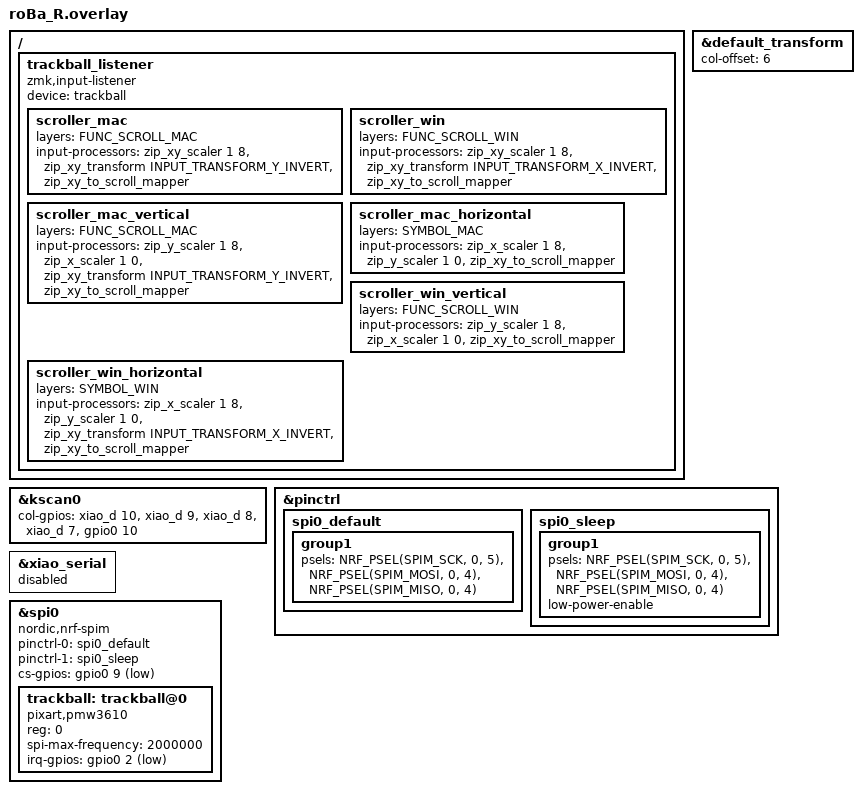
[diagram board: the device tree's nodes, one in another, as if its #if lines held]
#include "roBa.dtsi"
#include <input/processors.dtsi>
#include <dt-bindings/zmk/input_transform.h>

#define FUNC_SCROLL_WIN 6
#define FUNC_SCROLL_MAC 7


&default_transform {
    col-offset = <6>;
};

&kscan0 {
        col-gpios
            = <&xiao_d 10 GPIO_ACTIVE_HIGH>
            , <&xiao_d 9 GPIO_ACTIVE_HIGH> 
            , <&xiao_d 8 GPIO_ACTIVE_HIGH> 
            , <&xiao_d 7 GPIO_ACTIVE_HIGH> 
            , <&gpio0 10 GPIO_ACTIVE_HIGH>
            ;
};

/ {
    trackball_listener {
        compatible = "zmk,input-listener";
        device = <&trackball>;

        #ifndef MOD_SCROLL_MODE
        // Macの場合
        scroller_mac {
            layers = <FUNC_SCROLL_MAC>;
            input-processors =
                <&zip_xy_scaler 1 8>,
                <&zip_xy_transform INPUT_TRANSFORM_Y_INVERT>,
                <&zip_xy_to_scroll_mapper>;
        };

        // Windowsの場合
        scroller_win {
            layers = <FUNC_SCROLL_WIN>;
            input-processors =
                <&zip_xy_scaler 1 8>,
                <&zip_xy_transform INPUT_TRANSFORM_X_INVERT>,
                <&zip_xy_to_scroll_mapper>;
        };
        #endif

        #ifdef MOD_SCROLL_MODE
        // Mac
        scroller_mac_vertical {
            layers = <FUNC_SCROLL_MAC>;
            input-processors =
                <&zip_y_scaler 1 8>,
                <&zip_x_scaler 1 0>,
                <&zip_xy_transform INPUT_TRANSFORM_Y_INVERT>,
                <&zip_xy_to_scroll_mapper>;
        };

        scroller_mac_horizontal {
            layers = <SYMBOL_MAC>;
            input-processors =
                <&zip_x_scaler 1 8>,
                <&zip_y_scaler 1 0>,
                <&zip_xy_to_scroll_mapper>;
        };

        // Windows
        scroller_win_vertical {
            layers = <FUNC_SCROLL_WIN>;
            input-processors =
                <&zip_y_scaler 1 8>,
                <&zip_x_scaler 1 0>,
                <&zip_xy_to_scroll_mapper>;
        };

        scroller_win_horizontal {
            layers = <SYMBOL_WIN>;
            input-processors =
                <&zip_x_scaler 1 8>,
                <&zip_y_scaler 1 0>,
                <&zip_xy_transform INPUT_TRANSFORM_X_INVERT>,
                <&zip_xy_to_scroll_mapper>;
        };
        #endif
    };
};
&pinctrl {
    spi0_default: spi0_default {
        group1 {
            psels = <NRF_PSEL(SPIM_SCK, 0, 5)>,
                <NRF_PSEL(SPIM_MOSI, 0, 4)>,
                <NRF_PSEL(SPIM_MISO, 0, 4)>;
        };
    };

    spi0_sleep: spi0_sleep {
        group1 {
            psels = <NRF_PSEL(SPIM_SCK, 0, 5)>,
                <NRF_PSEL(SPIM_MOSI, 0, 4)>,
                <NRF_PSEL(SPIM_MISO, 0, 4)>;
            low-power-enable;
        };
    };
};

&xiao_serial { status = "disabled"; };

&spi0 {
    status = "okay";
    compatible = "nordic,nrf-spim";
    pinctrl-0 = <&spi0_default>;
    pinctrl-1 = <&spi0_sleep>;
    pinctrl-names = "default", "sleep";
    cs-gpios = <&gpio0 9 GPIO_ACTIVE_LOW>;

    trackball: trackball@0 {
        status = "okay";
        compatible = "pixart,pmw3610";
        reg = <0>;
        spi-max-frequency = <2000000>;
        irq-gpios = <&gpio0 2 (GPIO_ACTIVE_LOW | GPIO_PULL_UP)>;
    };
};
